# CY8C5888AXI_LP096 register map
File version: 0.1
CY8C58LP
Registers are 8-bit, read-write, no defined reset value unless marked. A register's access mark holds for its fields unless they carry their own. Offsets are from the block's base; lines under a group give offsets from that group; [hi:lo] are bit positions; {n}, {i} and the like mark numbered series; 'fields as' and 'values as' point back to an identical list; <NAME> marks a mode.

## Memory map
0x00000000 PWM
0x00000000 UART

## PWM
Base 0x00000000
0x4000642C PWM_COMPARE_1 16-bit — UDB.D0 - Assigned Compare1 Value
0x4000643C PWM_COMPARE_2 16-bit — UDB.D1 - Assigned Compare2 Value
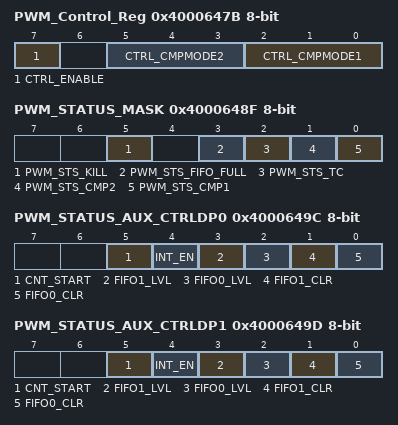
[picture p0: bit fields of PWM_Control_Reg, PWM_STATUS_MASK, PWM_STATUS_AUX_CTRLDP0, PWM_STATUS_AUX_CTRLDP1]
0x4000647B PWM_Control_Reg — UDB Control Register - Assigned Control Register Value
  [7] CTRL_ENABLE — Enable the PWM
  [5:3] CTRL_CMPMODE2 — Compare mode 2
  [2:0] CTRL_CMPMODE1 — Compare mode 1
0x4000648F PWM_STATUS_MASK — UDB Status bits Interrupt Mask Enable Register
  [5] PWM_STS_KILL ro — Enables the Interrupt on Kill
  [3] PWM_STS_FIFO_FULL ro — FIFO Full Status Mask
  [2] PWM_STS_TC ro — Enables the Interrupt on Terminal Count
  [1] PWM_STS_CMP2 ro — Enables the Interrupt on Compare 2
  [0] PWM_STS_CMP1 ro — Enables the Interrupt on Compare 1
0x4000649C PWM_STATUS_AUX_CTRLDP0 — UDB Auxilliary Control Register
  [5] CNT_START — FIFO0 clear
    0=E_CNT_START0 (Disable counter); 1=E_CNT_START1 (Enable counter)
  [4] INT_EN
    0=E_INT_EN0 (Interrupt disabled); 1=E_INT_EN1 (Interrupt enabled)
  [3] FIFO1_LVL — FIFO level
    0=E_FIFO_LVL_0 (FIFO LVL: input mode: FIFO not full; output mode: FIFO not empty); 1=E_FIFO_LVL_1 (FIFO LVL: input mode: FIFO at least 1/2 empty; output mode: FIFO at least 1/2 full)
  [2] FIFO0_LVL — FIFO level
    values as FIFO1_LVL
  [1] FIFO1_CLR — FIFO1 clear
    0=E_FIFO_CLR_0 (Normal FIFO operation); 1=E_FIFO_CLR_1 (Clear FIFO state)
  [0] FIFO0_CLR — FIFO0 clear
    values as FIFO1_CLR
0x4000649D PWM_STATUS_AUX_CTRLDP1 — UDB Auxilliary Control Register
  fields as PWM_STATUS_AUX_CTRLDP0

## UART
Base 0x00000000
0x4000642E RX_UART_RX_ADDRESS1 — RX Address1 Register
0x4000643E RX_UART_RX_ADDRESS2 — RX Address2 Register
0x40006448 TX_UART_TX_DATA — TX Data Register
0x4000644E RX_UART_RX_DATA — RX Data Register
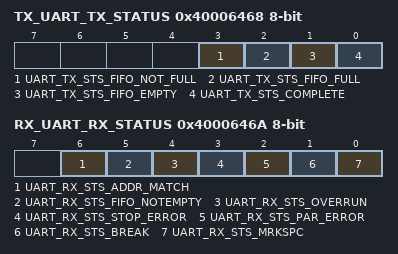
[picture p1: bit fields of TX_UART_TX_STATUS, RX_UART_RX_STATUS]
0x40006468 TX_UART_TX_STATUS — TX status register
  [3] UART_TX_STS_FIFO_NOT_FULL ro, [2] UART_TX_STS_FIFO_FULL ro, [1] UART_TX_STS_FIFO_EMPTY ro, [0] UART_TX_STS_COMPLETE ro
0x4000646A RX_UART_RX_STATUS — RX status register
  [6] UART_RX_STS_ADDR_MATCH ro, [5] UART_RX_STS_FIFO_NOTEMPTY ro, [4] UART_RX_STS_OVERRUN ro, [3] UART_RX_STS_STOP_ERROR ro, [2] UART_RX_STS_PAR_ERROR ro, [1] UART_RX_STS_BREAK ro, [0] UART_RX_STS_MRKSPC ro
